# H5 register map
Vendor: Allwinner; Series: H5; File version: 0.1
CPU: 0, little endian, MPU, no FPU, 0 interrupt priority bits
Registers are 32-bit, read-write, reset 0x0 unless marked. A register's access mark holds for its fields unless they carry their own. Offsets are from the block's base; [hi:lo] are bit positions; {n}, {i} and the like mark numbered series.

## OWA
Base 0x01C21000
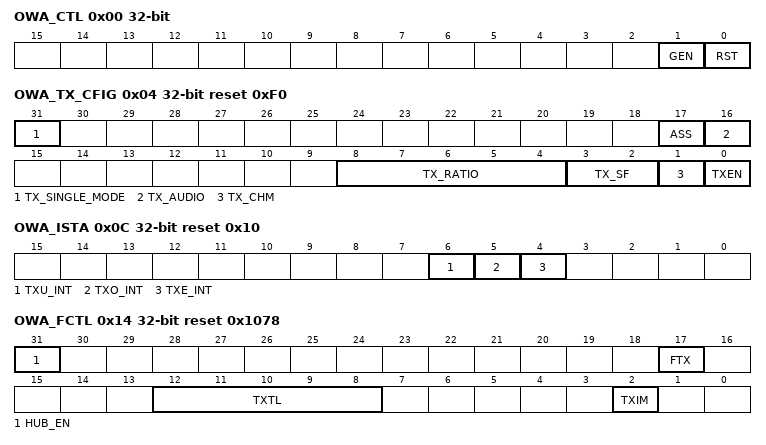
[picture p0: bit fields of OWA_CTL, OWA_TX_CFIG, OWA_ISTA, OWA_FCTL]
0x00 OWA_CTL
  [1] GEN — Global Enable A disable on this bit overrides any other block or channel enables and flushes all FIFOs. 0: Disable 1: Enable
    0=Disable; 1=Enable
  [0] RST — Reset 0: Normal 1: Reset Self clear to 0.
    0=Normal; 1=Reset Self clear to 0
0x04 OWA_TX_CFIG reset 0xF0 — OWA TX Configuration Register
  [31] TX_SINGLE_MODE — Tx Single Channel Mode 0: Disable 1: Enable
    0=Disable; 1=Enable
  [17] ASS — Audio Sample Select with TX FIFO Underrun When 0: Sending 0 1: Sending the last audio This bit is only valid in PCM mode
    0=Sending_0; 1=Sending the last audio This bit is only valid in PCM mode
  [16] TX_AUDIO — TX Data Type 0: Linear PCM (Valid bit of both sub-frame set to 0 ) 1: Non-audio(Valid bit of both sub-frame set to 1)
    0=Linear PCM (Valid bit of both sub-frame set to 0 ); 1=non_audio_openingparen_Valid_bit (Non-audio(Valid bit of both sub-frame set to 1))
  [8:4] TX_RATIO — TX Clock Divide Ratio Clock divide ratio = TX TATIO +1
  [3:2] TX_SF — TX Sample Format 00: 16 bits 01: 20 bits 10: 24 bits 11: Reserved
    0=_16_bits; 1=_20_bits; 2=_24_bits
  [1] TX_CHM — CHSTMODE 0: Channel status A&B set to 0 1: Channel status A&B generated form TX_CHSTA
    0=Channel_status_A_amp_B_set (Channel status A&B set to 0); 1=Channel_status_A_amp_B_generated (Channel status A&B generated form TX_CHSTA)
  [0] TXEN — 0: Disabled 1: Enabled
    0=Disabled; 1=Enabled
0x0C OWA_ISTA reset 0x10 — OWA Interrupt Status Register
  [6] TXU_INT — TX FIFO Underrun Pending Interrupt 0: No Pending IRQ 1: FIFO Underrun Pending Interrupt W iti g to lea this i te upt
    0=No Pending IRQ; 1=FIFO (FIFO Underrun Pending Interrupt W iti g to lea this i te upt)
  [5] TXO_INT — TX FIFO Overrun Pending Interrupt 0: No Pending IRQ 1: FIFO Overrun Pending Interrupt W iti g to lea this i te upt
    0=No Pending IRQ; 1=FIFO (FIFO Overrun Pending Interrupt W iti g to lea this i te upt)
  [4] TXE_INT — TX FIFO Empty Pending Interrupt 0: No Pending IRQ 1: FIFO Empty Pending Interrupt W iti g to lea this i te upt o auto ati all lea if t he interrupt condition fails.
    0=No Pending IRQ; 1=FIFO (FIFO Empty Pending Interrupt W iti g to lea this i te upt o auto ati all lea if t he interrupt condition fails.)
0x14 OWA_FCTL reset 0x1078 — OWA FIFO Control Register
  [31] HUB_EN — Audio Hub Enable 0 : Disable 1: Enable
    1=Enable
  [17] FTX — W iti g to flush TX FIFO, self lea to
  [12:8] TXTL — TX FIFO Empty Trigger Level Interrupt and DMA request trigger level for TX FIFO normal condition Trigger Level = TXTL
  [2] TXIM — TX FIFO Input Mode(Mode0, 1) 0: Valid data at the MSB of OWA_TXFIFO register 1: Valid data at the LSB of OWA_TXFIFO register Example for 20-bit transmitted audio sample: Mode 0: TXFIFO[23:0] = {APB_WDATA [ : ], h } Mode 1: TXFIFO[23:0] = {APB_WDATA [ : ], h }
    0=Valid data at the MSB of OWA_TXFIFO register; 1=Valid data at the LSB of OWA_TXFIFO register Example for 20-bit transmitted audio sample: Mode 0: TXFIFO[23:0] = {APB_WDATA [ : ], h } Mode 1: TXFIFO[23:0] = {APB_WDATA [ : ], h }
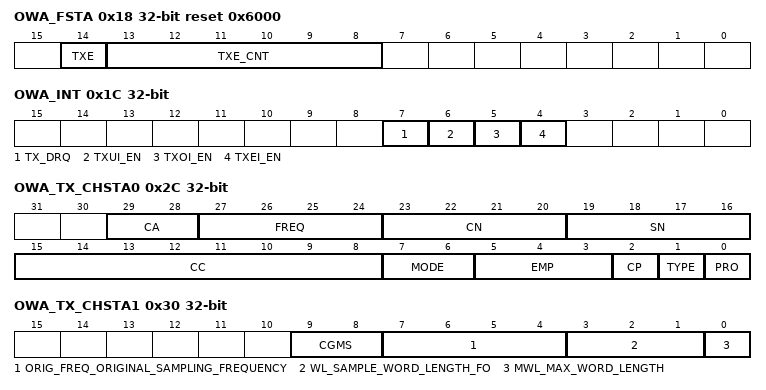
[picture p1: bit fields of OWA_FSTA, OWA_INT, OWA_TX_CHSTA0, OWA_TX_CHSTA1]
0x18 OWA_FSTA reset 0x6000 — OWA FIFO Status Register
  [14] TXE ro — TX FIFO Empty (indicate FIFO is not full) 0: No room for new sample in TX FIFO 1: More than one room for new sample in TX FIFO ( >=1 word )
    0=No room for new sample in TX FIFO; 1=More than one room for new sample in TX FIFO ( >=1 word )
  [13:8] TXE_CNT ro — TX FIFO Empty Space Word Counter
0x1C OWA_INT — OWA Interrupt Control Register
  [all] fields
    0=Disable; 1=Enable
  [7] TX_DRQ — TX FIFO Empty DRQ Enable 0: Disable 1: Enable
  [6] TXUI_EN — TX FIFO Underrun Interrupt Enable 0: Disable 1: Enable
  [5] TXOI_EN — TX FIFO Overrun Interrupt Enable 0: Disable 1: Enable
  [4] TXEI_EN — TX FIFO Empty Interrupt Enable 0: Disable 1: Enable
0x20 OWA_TXFIFO
  [31:0] TX_DATA wo — Transmitting A, B channel data should be written this register one by one. The A channel data is first and then the B channel data.
0x24 OWA_TX_CNT — OWA TX Counter Register
  [31:0] TX_CNT — TX Sample Counter The audio sample number of sending into TXFIFO. When one sample is put into TXFIFO by DMA or by host IO, the TX sample counter register increases by one. The TX sample counter register can be set to any initial value at any time. After updated by the initial value, the counter register should count on base of this initial value.
0x2C OWA_TX_CHSTA0 — OWA TX Channel Status Register0
  [29:28] CA — Clock Accuracy 00: Level 2 01: Level 1 10: Level 3 11: Not matched
    0=Level_2; 1=Level_1; 2=Level_3; 3=Not_matched
  [27:24] FREQ — Sampling Frequency 0000: 44.1kHz 0001: Not indicated 0010: 48kHz 0011: 32kHz 0100: 22.05kHz 0101: Reserved 0110: 24kHz 0111: Reserved 1000: Reserved 1001: 768kHz 1010: 96kHz 1011: Reserved 1100:176.4kHz 1101: Reserved 1110: 192kHz 1111: Reserved
    0=_44_point_1kHz (44.1kHz); 1=Not_indicated; 2=_48kHz; 3=_32kHz; 4=_22_point_05kHz (22.05kHz); 6=_24kHz; 9=_768kHz; 10=_96kHz; 14=_192kHz
  [23:20] CN — Channel Number
  [19:16] SN — Source Number
  [15:8] CC — Category Code Indicates the kind of equipment that generates the digital audio interface signal.
  [7:6] MODE — Mode 00: Default Mode 01~11: Reserved
    0=Default Mode 01~11: Reserved
  [5:3] EMP — Emphasis Additional format information Fo it = , Li ea PCM audio ode: 000: 2 audio channels without pre-emphasis 0 : audio ha els ith μs / μs p e -emphasis 010: Reserved (for 2 audio channels with pre-emphasis) 011: Reserved (for 2 audio channels with pre-emphasis) 100~111: Reserved Fo it = , othe tha Li ea PCM appli atio s: 000: Default state 001~111: Reserved
  [2] CP — Copyright 0: Copyright is asserted 1: No copyright is asserted
    0=Copyright is asserted; 1=No copyright is asserted
  [1] TYPE — Audio Data Type 0: Linear PCM Samples 1: For none-linear PCM audio such as AC3, DTS, MPEG audio
    0=Linear PCM Samples; 1=For (For none-linear PCM audio such as AC3, DTS, MPEG audio)
  [0] PRO — Application Type 0: Consumer Application 1: Professional Application This it ust e fi ed to
    0=Consumer Application; 1=Professional Application This it ust e fi ed to
0x30 OWA_TX_CHSTA1 — OWA TX Channel Status Register1
  [9:8] CGMS — CGMS_A 00: Copying is permitted without restriction 01: One generation of copies may be made 10: Condition not be used 11: No copying is permitted
    0=Copying is permitted without restriction; 1=One (One generation of copies may be made); 2=Condition not be used; 3=No copying is permitted
  [7:4] ORIG_FREQ_ORIGINAL_SAMPLING_FREQUENCY — ORIG_FREQ Original Sampling Frequency 0000: Not indicated 0001: 192kHz 0010: 12kHz 0011: 176.4kHz 0100: Reserved 0101: 96kHz 0110: 8kHz 0111: 88.2kHz 1000: 16kHz 1001: 24kHz 1010: 11.025kHz 1011: 22.05kHz 1100: 32kHz 1101: 48kHz 1110: Reserved 1111: 44.1kHz
    0=Not_indicated; 1=_192kHz; 2=_12kHz; 3=_176_point_4kHz (176.4kHz); 5=_96kHz; 6=_8kHz; 7=_88_point_2kHz (88.2kHz); 8=_16kHz; 9=_24kHz; 10=_11_point_025kHz (11.025kHz); 11=_22_point_05kHz (22.05kHz); 12=_32kHz; 13=_48kHz; 15=_44_point_1kHz (44.1kHz)
  [3:1] WL_SAMPLE_WORD_LENGTH_FO — WL Sample Word Length Fo it = : 000: Not indicated 001: 16 bits 010: 18 bits 100: 19 bits 101: 20 bits 110: 17 bits 111: Reserved Fo it = : 000: Not indicated 001: 20 bits 010: 22 bits 100: 23 bits 101: 24 bits 110: 21 bits 111: Reserved
  [0] MWL_MAX_WORD_LENGTH — MWL Max Word Length 0: Maximum audio sample word length is 20 bits 1: Maximum audio sample word length is 24 bits
    0=Maximum audio sample word length is 20 bits; 1=Maximum audio sample word length is 24 bits
